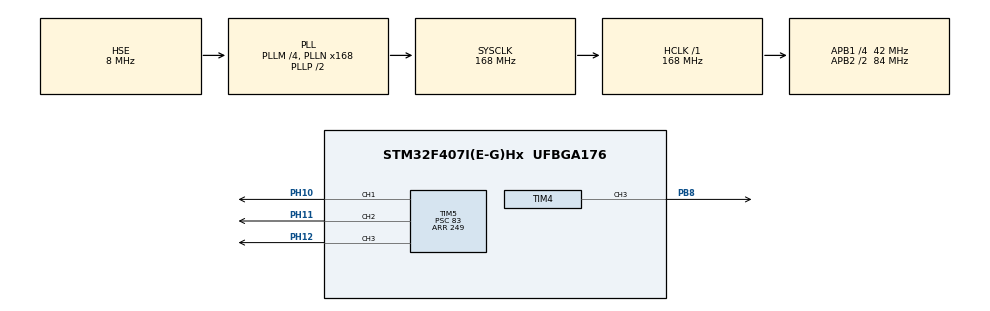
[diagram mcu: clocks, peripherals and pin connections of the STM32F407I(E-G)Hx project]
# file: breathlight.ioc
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Mcu.Family=STM32F4
Mcu.Name=STM32F407I(E-G)Hx
Mcu.Package=UFBGA176
NVIC.PriorityGroup=NVIC_PRIORITYGROUP_4
PB8.Signal=S_TIM4_CH3
PH0-OSC_IN.Mode=HSE-External-Oscillator
PH0-OSC_IN.Signal=RCC_OSC_IN
PH1-OSC_OUT.Mode=HSE-External-Oscillator
PH1-OSC_OUT.Signal=RCC_OSC_OUT
PH10.Signal=S_TIM5_CH1
PH11.Signal=S_TIM5_CH2
PH12.Signal=S_TIM5_CH3
ProjectManager.HeapSize=0x200
ProjectManager.StackSize=0x400
ProjectManager.TargetToolchain=CMake
RCC.48MHZClocksFreq_Value=84000000
RCC.AHBFreq_Value=168000000
RCC.APB1CLKDivider=RCC_HCLK_DIV4
RCC.APB1Freq_Value=42000000
RCC.APB1TimFreq_Value=84000000
RCC.APB2CLKDivider=RCC_HCLK_DIV2
RCC.APB2Freq_Value=84000000
RCC.APB2TimFreq_Value=168000000
RCC.CortexFreq_Value=168000000
RCC.HCLKFreq_Value=168000000
RCC.HSE_VALUE=8000000
RCC.HSI_VALUE=16000000
RCC.LSE_VALUE=32768
RCC.PLLM=4
RCC.PLLN=168
RCC.PLLSourceVirtual=RCC_PLLSOURCE_HSE
RCC.SYSCLKFreq_VALUE=168000000
RCC.SYSCLKSource=RCC_SYSCLKSOURCE_PLLCLK
RCC.VCOOutputFreq_Value=336000000
SH.S_TIM4_CH3.0=TIM4_CH3,PWM Generation3 CH3
SH.S_TIM5_CH1.0=TIM5_CH1,PWM Generation1 CH1
SH.S_TIM5_CH2.0=TIM5_CH2,PWM Generation2 CH2
SH.S_TIM5_CH3.0=TIM5_CH3,PWM Generation3 CH3
TIM4.Channel-PWM\ Generation3\ CH3=TIM_CHANNEL_3
TIM4.Period=249
TIM4.Prescaler=83
TIM4.Pulse-PWM\ Generation3\ CH3=50
TIM5.Channel-PWM\ Generation1\ CH1=TIM_CHANNEL_1
TIM5.Channel-PWM\ Generation2\ CH2=TIM_CHANNEL_2
TIM5.Channel-PWM\ Generation3\ CH3=TIM_CHANNEL_3
TIM5.Period=249
TIM5.Prescaler=83
TIM5.Pulse-PWM\ Generation1\ CH1=100
TIM5.Pulse-PWM\ Generation2\ CH2=125
TIM5.Pulse-PWM\ Generation3\ CH3=150
VP_TIM4_VS_ClockSourceINT.Mode=Internal
board=custom

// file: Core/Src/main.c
/* USER CODE BEGIN Header */
/**
  ******************************************************************************
  * @file           : main.c
  * @brief          : Main program body
  ******************************************************************************
  * @attention
  *
  * Copyright (c) 2026 STMicroelectronics.
  * All rights reserved.
  *
  * This software is licensed under terms that can be found in the LICENSE file
  * in the root directory of this software component.
  * If no LICENSE file comes with this software, it is provided AS-IS.
  *
  ******************************************************************************
  */
/* USER CODE END Header */
#include "main.h"

TIM_HandleTypeDef htim4;
TIM_HandleTypeDef htim5;

void SystemClock_Config(void);
static void MX_GPIO_Init(void);
static void MX_TIM4_Init(void);
static void MX_TIM5_Init(void);

int main(void)
{ HAL_Init(); // 1. 初始化HAL库

  /* Configure the system clock */
  SystemClock_Config();

  /* Initialize all configured peripherals */
  MX_GPIO_Init();
  MX_TIM4_Init();
  MX_TIM5_Init();
  /* USER CODE BEGIN 1 */
  /* USER CODE BEGIN 2 */
  HAL_TIM_PWM_Start(&htim5, TIM_CHANNEL_1); // 蓝灯 PH10
  HAL_TIM_PWM_Start(&htim5, TIM_CHANNEL_2); // 绿灯 PH11
  HAL_TIM_PWM_Start(&htim5, TIM_CHANNEL_3); // 红灯 PH12
  HAL_TIM_PWM_Start(&htim4, TIM_CHANNEL_3);
  /* USER CODE END 2 */
  /* USER CODE END 1 */

  /* MCU Configuration--------------------------------------------------------*/

  /* Reset of all peripherals, Initializes the Flash interface and the Systick. */
  HAL_Init();

  /* Configure the system clock */
  SystemClock_Config();

  /* Initialize all configured peripherals */
  MX_GPIO_Init();
  MX_TIM4_Init();
  MX_TIM5_Init();

  /* Infinite loop */
  /* USER CODE BEGIN WHILE */
  while (1)
  {
    for (int i = 0; i <= 250; i += 5) {
        __HAL_TIM_SET_COMPARE(&htim5, TIM_CHANNEL_3, i);
        HAL_Delay(10);
    }
    // 让红灯从亮到暗
    for (int i = 250; i >= 0; i -= 5) {
        __HAL_TIM_SET_COMPARE(&htim5, TIM_CHANNEL_3, i);
        HAL_Delay(10);
    }

  }
  /* USER CODE END 3 */
}

void SystemClock_Config(void)
{
  RCC_OscInitTypeDef RCC_OscInitStruct = {0};
  RCC_ClkInitTypeDef RCC_ClkInitStruct = {0};

  /** Configure the main internal regulator output voltage
  */
  __HAL_RCC_PWR_CLK_ENABLE();
  __HAL_PWR_VOLTAGESCALING_CONFIG(PWR_REGULATOR_VOLTAGE_SCALE1);

  /** Initializes the RCC Oscillators according to the specified parameters
  * in the RCC_OscInitTypeDef structure.
  */
  RCC_OscInitStruct.OscillatorType = RCC_OSCILLATORTYPE_HSE;
  RCC_OscInitStruct.HSEState = RCC_HSE_ON;
  RCC_OscInitStruct.PLL.PLLState = RCC_PLL_ON;
  RCC_OscInitStruct.PLL.PLLSource = RCC_PLLSOURCE_HSE;
  RCC_OscInitStruct.PLL.PLLM = 4;
  RCC_OscInitStruct.PLL.PLLN = 168;
  RCC_OscInitStruct.PLL.PLLP = RCC_PLLP_DIV2;
  RCC_OscInitStruct.PLL.PLLQ = 4;
  if (HAL_RCC_OscConfig(&RCC_OscInitStruct) != HAL_OK)
  {
    Error_Handler();
  }

  /** Initializes the CPU, AHB and APB buses clocks
  */
  RCC_ClkInitStruct.ClockType = RCC_CLOCKTYPE_HCLK|RCC_CLOCKTYPE_SYSCLK
                              |RCC_CLOCKTYPE_PCLK1|RCC_CLOCKTYPE_PCLK2;
  RCC_ClkInitStruct.SYSCLKSource = RCC_SYSCLKSOURCE_PLLCLK;
  RCC_ClkInitStruct.AHBCLKDivider = RCC_SYSCLK_DIV1;
  RCC_ClkInitStruct.APB1CLKDivider = RCC_HCLK_DIV4;
  RCC_ClkInitStruct.APB2CLKDivider = RCC_HCLK_DIV2;

  if (HAL_RCC_ClockConfig(&RCC_ClkInitStruct, FLASH_LATENCY_5) != HAL_OK)
  {
    Error_Handler();
  }
}

static void MX_TIM4_Init(void)
{

  TIM_ClockConfigTypeDef sClockSourceConfig = {0};
  TIM_MasterConfigTypeDef sMasterConfig = {0};
  TIM_OC_InitTypeDef sConfigOC = {0};

  htim4.Instance = TIM4;
  htim4.Init.Prescaler = 83;
  htim4.Init.CounterMode = TIM_COUNTERMODE_UP;
  htim4.Init.Period = 249;
  htim4.Init.ClockDivision = TIM_CLOCKDIVISION_DIV1;
  htim4.Init.AutoReloadPreload = TIM_AUTORELOAD_PRELOAD_DISABLE;
  if (HAL_TIM_Base_Init(&htim4) != HAL_OK)
  {
    Error_Handler();
  }
  sClockSourceConfig.ClockSource = TIM_CLOCKSOURCE_INTERNAL;
  if (HAL_TIM_ConfigClockSource(&htim4, &sClockSourceConfig) != HAL_OK)
  {
    Error_Handler();
  }
  if (HAL_TIM_PWM_Init(&htim4) != HAL_OK)
  {
    Error_Handler();
  }
  sMasterConfig.MasterOutputTrigger = TIM_TRGO_RESET;
  sMasterConfig.MasterSlaveMode = TIM_MASTERSLAVEMODE_DISABLE;
  if (HAL_TIMEx_MasterConfigSynchronization(&htim4, &sMasterConfig) != HAL_OK)
  {
    Error_Handler();
  }
  sConfigOC.OCMode = TIM_OCMODE_PWM1;
  sConfigOC.Pulse = 50;
  sConfigOC.OCPolarity = TIM_OCPOLARITY_HIGH;
  sConfigOC.OCFastMode = TIM_OCFAST_DISABLE;
  if (HAL_TIM_PWM_ConfigChannel(&htim4, &sConfigOC, TIM_CHANNEL_3) != HAL_OK)
  {
    Error_Handler();
  }
  HAL_TIM_MspPostInit(&htim4);

}

static void MX_TIM5_Init(void)
{

  TIM_MasterConfigTypeDef sMasterConfig = {0};
  TIM_OC_InitTypeDef sConfigOC = {0};

  htim5.Instance = TIM5;
  htim5.Init.Prescaler = 83;
  htim5.Init.CounterMode = TIM_COUNTERMODE_UP;
  htim5.Init.Period = 249;
  htim5.Init.ClockDivision = TIM_CLOCKDIVISION_DIV1;
  htim5.Init.AutoReloadPreload = TIM_AUTORELOAD_PRELOAD_DISABLE;
  if (HAL_TIM_PWM_Init(&htim5) != HAL_OK)
  {
    Error_Handler();
  }
  sMasterConfig.MasterOutputTrigger = TIM_TRGO_RESET;
  sMasterConfig.MasterSlaveMode = TIM_MASTERSLAVEMODE_DISABLE;
  if (HAL_TIMEx_MasterConfigSynchronization(&htim5, &sMasterConfig) != HAL_OK)
  {
    Error_Handler();
  }
  sConfigOC.OCMode = TIM_OCMODE_PWM1;
  sConfigOC.Pulse = 100;
  sConfigOC.OCPolarity = TIM_OCPOLARITY_HIGH;
  sConfigOC.OCFastMode = TIM_OCFAST_DISABLE;
  if (HAL_TIM_PWM_ConfigChannel(&htim5, &sConfigOC, TIM_CHANNEL_1) != HAL_OK)
  {
    Error_Handler();
  }
  sConfigOC.Pulse = 125;
  if (HAL_TIM_PWM_ConfigChannel(&htim5, &sConfigOC, TIM_CHANNEL_2) != HAL_OK)
  {
    Error_Handler();
  }
  sConfigOC.Pulse = 150;
  if (HAL_TIM_PWM_ConfigChannel(&htim5, &sConfigOC, TIM_CHANNEL_3) != HAL_OK)
  {
    Error_Handler();
  }
  HAL_TIM_MspPostInit(&htim5);

}

static void MX_GPIO_Init(void)
{

  /* GPIO Ports Clock Enable */
  __HAL_RCC_GPIOB_CLK_ENABLE();
  __HAL_RCC_GPIOH_CLK_ENABLE();

}

void Error_Handler(void)
{
  __disable_irq();
  while (1)
  {
  }
}
